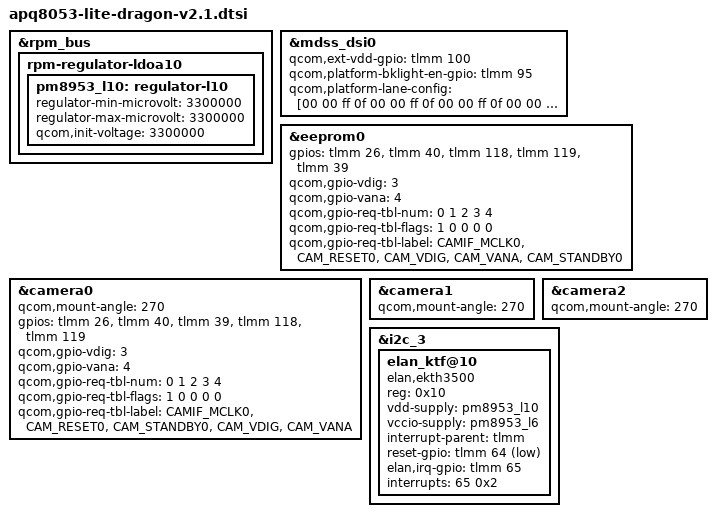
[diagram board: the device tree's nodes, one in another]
/*
 * Copyright (c) 2017-2018, The Linux Foundation. All rights reserved.
 *
 * This program is free software; you can redistribute it and/or modify
 * it under the terms of the GNU General Public License version 2 and
 * only version 2 as published by the Free Software Foundation.
 *
 * This program is distributed in the hope that it will be useful,
 * but WITHOUT ANY WARRANTY; without even the implied warranty of
 * MERCHANTABILITY or FITNESS FOR A PARTICULAR PURPOSE.  See the
 * GNU General Public License for more details.
 */

#include "apq8053-lite-dragon.dtsi"

&rpm_bus {
	rpm-regulator-ldoa10 {
		status = "okay";
		pm8953_l10: regulator-l10 {
			regulator-min-microvolt = <3300000>;
			regulator-max-microvolt = <3300000>;
			qcom,init-voltage = <3300000>;
			status = "okay";
		};
	};
};

&mdss_dsi0 {
	qcom,ext-vdd-gpio = <&tlmm 100 0>;
	qcom,platform-bklight-en-gpio = <&tlmm 95 0>;

	/delete-property/ vdd-supply;
	qcom,platform-lane-config = [00 00 ff 0f
				00 00 ff 0f
				00 00 ff 0f
				00 00 ff 0f
				00 00 ff 8f];
};

&eeprom0 {
	gpios = <&tlmm 26 0>,
		<&tlmm 40 0>,
		<&tlmm 118 0>,
		<&tlmm 119 0>,
		<&tlmm 39 0>;
	qcom,gpio-vdig = <3>;
	qcom,gpio-vana = <4>;
	qcom,gpio-req-tbl-num = <0 1 2 3 4>;
	qcom,gpio-req-tbl-flags = <1 0 0 0 0>;
	qcom,gpio-req-tbl-label = "CAMIF_MCLK0",
			"CAM_RESET0",
			"CAM_VDIG",
			"CAM_VANA",
			"CAM_STANDBY0";
};

&camera0 {
	qcom,mount-angle = <270>;
	gpios = <&tlmm 26 0>,
		<&tlmm 40 0>,
		<&tlmm 39 0>,
		<&tlmm 118 0>,
		<&tlmm 119 0>;
	qcom,gpio-vdig = <3>;
	qcom,gpio-vana = <4>;
	qcom,gpio-req-tbl-num = <0 1 2 3 4>;
	qcom,gpio-req-tbl-flags = <1 0 0 0 0>;
	qcom,gpio-req-tbl-label = "CAMIF_MCLK0",
			"CAM_RESET0",
			"CAM_STANDBY0",
			"CAM_VDIG",
			"CAM_VANA";
};

&camera1 {
	qcom,mount-angle = <270>;
};

&camera2{
	qcom,mount-angle = <270>;
};

&i2c_3 {
	status = "okay";
	elan_ktf@10 {
		compatible = "elan,ekth3500";
		reg = <0x10>;
		vdd-supply = <&pm8953_l10>;
		vccio-supply = <&pm8953_l6>;
		interrupt-parent = <&tlmm>;
		reset-gpio = <&tlmm 64 GPIO_ACTIVE_LOW>;
		elan,irq-gpio = <&tlmm 65 0x2008>;
		interrupts = <65 0x2>;
	};
};
